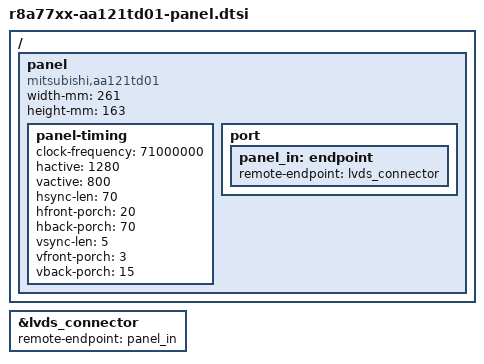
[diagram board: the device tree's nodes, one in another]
/*
 * Common file for the AA121TD01 panel connected to Renesas R-Car boards
 *
 * Copyright (C) 2015 Renesas Electronics Corp.
 *
 * This file is licensed under the terms of the GNU General Public License
 * version 2.  This program is licensed "as is" without any warranty of any
 * kind, whether express or implied.
 */

/ {
	panel {
		compatible = "mitsubishi,aa121td01", "panel-dpi";

		width-mm = <261>;
		height-mm = <163>;

		panel-timing {
			/* 1280x800 @60Hz */
			clock-frequency = <71000000>;
			hactive = <1280>;
			vactive = <800>;
			hsync-len = <70>;
			hfront-porch = <20>;
			hback-porch = <70>;
			vsync-len = <5>;
			vfront-porch = <3>;
			vback-porch = <15>;
		};

		port {
			panel_in: endpoint {
				remote-endpoint = <&lvds_connector>;
			};
		};
	};
};

&lvds_connector {
	remote-endpoint = <&panel_in>;
};
